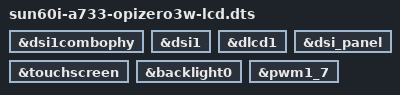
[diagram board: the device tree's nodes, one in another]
/dts-v1/;
/plugin/;

/ {
	fragment@0 {
		target = <&dsi1combophy>;

		__overlay__ {
			status = "okay";
		};
	};
	fragment@1 {
		target = <&dsi1>;

		__overlay__ {
			status = "okay";
		};
	};
	fragment@2 {
		target = <&dlcd1>;

		__overlay__ {
			status = "okay";
		};
	};
	fragment@3 {
		target = <&dsi_panel>;

		__overlay__ {
			status = "okay";
		};
	};
	fragment@4 {
		target = <&touchscreen>;

		__overlay__ {
			status = "okay";
		};
	};

	fragment@5 {
		target = <&backlight0>;

		__overlay__ {
			status = "okay";
		};
	};

	fragment@6 {
		target = <&pwm1_7>;

		__overlay__ {
			status = "okay";
		};
	};
};

